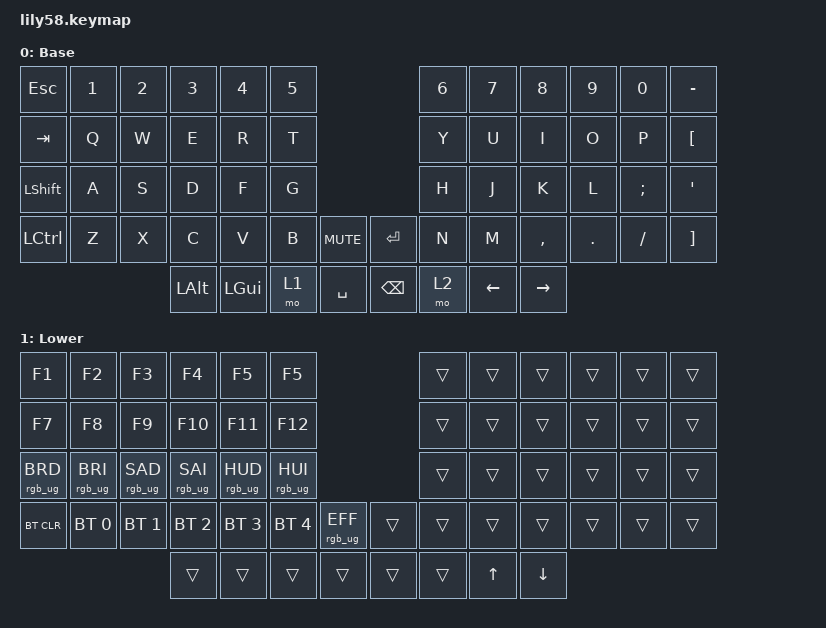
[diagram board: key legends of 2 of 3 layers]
/*
 * Copyright (c) 2020 The ZMK Contributors
 *
 * SPDX-License-Identifier: MIT
 */

#include <behaviors.dtsi>
#include <dt-bindings/zmk/keys.h>
#include <dt-bindings/zmk/bt.h>
#include <dt-bindings/zmk/ext_power.h>
#include <dt-bindings/zmk/rgb.h>
#include <dt-bindings/pinctrl/nrf-pinctrl.h>

&pinctrl {
	spi3_default: spi3_default {
		group1 {
			psels = <NRF_PSEL(SPIM_MOSI, 0, 6)>;
		};
	};

	spi3_sleep: spi3_sleep {
		group1 {
			psels = <NRF_PSEL(SPIM_MOSI, 0, 6)>;
			low-power-enable;
		};
	};
};

&spi3 {
	compatible = "nordic,nrf-spim";
	status = "okay";
	pinctrl-0 = <&spi3_default>;
	pinctrl-1 = <&spi3_sleep>;
	pinctrl-names = "default", "sleep";

	led_strip: ws2812@0 {
		compatible = "worldsemi,ws2812-spi";
		reg = <0>;
		spi-max-frequency = <4000000>;
		/* 29 per-key LEDs + 6 underglow LEDs on this half */
		chain-length = <35>;
		spi-one-frame = <0x70>;
		spi-zero-frame = <0x40>;
	};
};

/ {
	chosen {
		zmk,underglow = &led_strip;
	};
        // Activate ADJUST layer by pressing raise and lower
    conditional_layers {
        compatible = "zmk,conditional-layers";

        adjust_layer {
            if-layers = <1 2>;
            then-layer = <3>;
        };
    };
    keymap {
        compatible = "zmk,keymap";

        default_layer {
            display-name = "Base";
// ------------------------------------------------------------------------------------------------------------
// |  ESC  |   1   |   2   |   3   |   4   |   5   |                   |   6   |   7    |   8    |   9   |   0   |   -   |
// |  TAB  |   Q   |   W   |   E   |   R   |   T   |                   |   Y   |   U    |   I    |   O   |   P   |   [   |
// |  CTRL |   A   |   S   |   D   |   F   |   G   |                   |   H   |   J    |   K    |   L   |   ;   |   '   |
// | SHIFT |   Z   |   X   |   C   |   V   |   B   |  MUTE  |  | ENTER |   N   |   M    |   ,    |   .   |   /   |   ]   |
//                         |  ALT  |  GUI  | LOWER |  SPACE |  | BSPC  | RAISE |   ⬅   |   ⮕   |
            bindings = < 
&kp ESC   &kp N1 &kp N2 &kp N3   &kp N4   &kp N5                        &kp N6 &kp N7   &kp N8    &kp N9  &kp N0   &kp MINUS
&kp TAB   &kp Q  &kp W  &kp E    &kp R    &kp T                         &kp Y  &kp U    &kp I     &kp O   &kp P    &kp LBKT
&kp LSHFT &kp A  &kp S  &kp D    &kp F    &kp G                         &kp H  &kp J    &kp K     &kp L   &kp SEMI &kp SQT
&kp LCTRL &kp Z  &kp X  &kp C    &kp V    &kp B  &kp C_MUTE   &kp RET   &kp N  &kp M    &kp COMMA &kp DOT &kp FSLH &kp RBKT
                        &kp LALT &kp LGUI &mo 1  &kp SPACE    &kp BSPC  &mo 2  &kp LEFT &kp RIGHT
            >;

            sensor-bindings = <&inc_dec_kp C_VOL_UP C_VOL_DN &inc_dec_kp PG_UP PG_DN>;
        };

        lower_layer {
            display-name = "Lower";
// ------------------------------------------------------------------------------------------------------------
// |   F1    |   F2    |   F3    |   F4    |   F5    |   F6    |                  |        |       |       |       |       |       |
// |   F7    |   F8    |   F9    |   F10   |   F11   |   F12   |                  |        |       |       |       |       |       |
// | RGB_BRD | RGB_BRI | RGB_SAD | RGB_SAI | RGB_HUD | RGB_HUI |                  |        |       |       |       |       |       |
// |  BTCL   |  BT0    |  BT1    |  BT2    |  BT3    |  BT4    | RGB_EFF|  |      |        |       |       |       |       |       |
//                               |         |         |         |        |  |      |        |   ⬆   |   ⬇   |
            bindings = <
&kp F1          &kp F2          &kp F3            &kp F4          &kp F5           &kp F5                                        &trans    &trans    &trans    &trans    &trans    &trans
&kp F7          &kp F8          &kp F9            &kp F10         &kp F11          &kp F12                                       &trans    &trans    &trans    &trans    &trans    &trans
&rgb_ug RGB_BRD &rgb_ug RGB_BRI &rgb_ug RGB_SAD   &rgb_ug RGB_SAI &rgb_ug RGB_HUD  &rgb_ug RGB_HUI                               &trans    &trans    &trans    &trans    &trans    &trans    
&bt BT_CLR      &bt BT_SEL 0    &bt BT_SEL 1      &bt BT_SEL 2    &bt BT_SEL 3     &bt BT_SEL 4     &rgb_ug RGB_EFF    &trans    &trans    &trans    &trans    &trans    &trans    &trans
                                                  &trans          &trans           &trans           &trans             &trans    &trans    &kp UP    &kp DOWN
            >;

             sensor-bindings = <&inc_dec_kp C_VOL_UP C_VOL_DN &inc_dec_kp PG_UP PG_DN>;
        };

        adjust_layer {
            display-name = "Adjust";
// ----------------------------------------------------------------------------------------------------------------------------
// | BTCLR  |  BT1    |  BT2    |   BT3   |   BT4   |   BT5   |                  |      |      |       |      |       |       |
// | EXTPWR | RGB_HUD | RGB_HUI | RGB_SAD | RGB_SAI | RGB_EFF |                  |      |      |       |      |       |       |
// |        | RGB_BRD | RGB_BRI |         |         |         |                  |      |      |       |      |       |       |
// |        |         |         |         |         |         | RGB_TOG | |      |      |      |       |      |       |       |
//                    |         |         |         |         |         | |      |      |      |       |      |
            bindings = <
&bt BT_CLR        &bt BT_SEL 0    &bt BT_SEL 1    &bt BT_SEL 2    &bt BT_SEL 3    &bt BT_SEL 4                            &trans &trans &trans &trans &trans &trans
&ext_power EP_TOG &rgb_ug RGB_HUD &rgb_ug RGB_HUI &rgb_ug RGB_SAD &rgb_ug RGB_SAI &rgb_ug RGB_EFF                         &trans &trans &trans &trans &trans &trans
&trans             &rgb_ug RGB_BRD &rgb_ug RGB_BRI &trans           &trans           &trans                                   &trans &trans &trans &trans &trans &trans
&trans             &trans           &trans           &trans           &trans           &trans            &trans &trans  &trans &trans &trans &trans &trans &trans
                                  &trans           &trans           &trans           &trans            &trans           &trans  &trans &trans &trans &trans
            >;
            sensor-bindings = <&inc_dec_kp C_VOL_UP C_VOL_DN>;
        };
         extra1 { status = "reserved"; };

        extra2 { status = "reserved"; };

        extra3 { status = "reserved"; };

        extra4 { status = "reserved"; };

        extra5 { status = "reserved"; };
    };
};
